# LPC8N04 register map
Vendor: nxp.com; File version: 1.0
CPU: CM0PLUS r0p0, little endian, no MPU, no FPU, VTOR, 2 interrupt priority bits
Registers are 32-bit, read-write, reset 0x0 unless marked. A register's access mark holds for its fields unless they carry their own. Offsets are from the block's base; [hi:lo] are bit positions; {n}, {i} and the like mark numbered series.

## TSENS — Temperature Sensor
Base 0x40060000
0x00 CR — Control register
  [0] START — sensor start bit. This bit is cleared by the temperature sensor at the end of the measurement.
0x04 DR — Data register. Contains result of conversion
  [15:0] DATA ro — Result of last conversion. Raw format is unsigned fixed point (0,5.11); calibrated format is signed (1, 9.6) 2-complement fixed point.
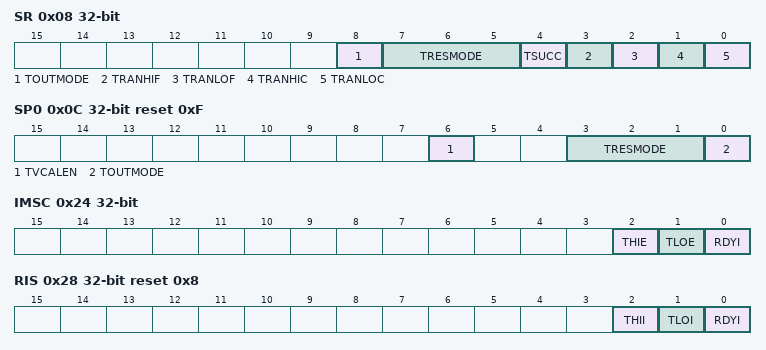
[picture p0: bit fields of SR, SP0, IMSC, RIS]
0x08 SR — Status register
  [8] TOUTMODE ro — used output mode
  [7:5] TRESMODE ro — used resolution mode
  [4] TSUCC ro — 1: successful conversion
  [3] TRANHIF ro — Fine range: 1: out of range (too large)
  [2] TRANLOF ro — Fine range: 1: out of range (too low)
  [1] TRANHIC ro — Coarse range: 1: out of range (too high)
  [0] TRANLOC ro — Coarse range: 1: out of range (too low)
0x0C SP0 reset 0xF — Setup register 0: set ADC and operation modes
  [6] TVCALEN — temperature sensor voltage calibration enable
  [3:1] TRESMODE — temperature sensor resolution mode. (0b010) 7 bit, (0b011) 8 bit, (0b100) 9 bit, (0b101) 10 bit, (0b110) 11 bits, (0b111) 12 bits (others not supported)
  [0] TOUTMODE — temperature sensor output mode. 0: raw data, 1: calibrated data
0x10 SP1 — Setup register 1: Calibration value 'A'
  [15:0] A — calibration factor ?A? unsigned fixed point (10.6)
0x14 SP2 — Setup register 2: Calibration value 'B'
  [15:0] B — calibration factor ?B? signed fixed point (10.6) 2-complement
0x18 SP3 — Setup register 3: Calibration value 'alpha'
  [15:0] ALPHA — calibration factor ?alpha? unsigned fixed point (6.10)
0x1C TLO — Low temperature threshold register
  [15:0] TLO — low-temperature threshold value in signed fixed point (10.6) 2-complement format.
0x20 THI — High temperature threshold register
  [15:0] THI — high-temperature threshold value in signed fixed point (10.6) 2-complement format.
0x24 IMSC — Interrupt Mask Set and Clear Register
  [2] THIE — Software should set this bit to enable interrupt when a temperature conversion is higher than the value stored in THI.
  [1] TLOE — Software should set this bit to enable interrupt when a temperature conversion is higher than the value stored in TLO.
  [0] RDYI — Software should set this bit to enable interrupt when a temperature conversion is ready on DR.
0x28 RIS reset 0x8 — Raw Interrupt Status Register
  [2] THII ro — This bit is 1 when a temperature conversion has finished and the value exceeds the threshold value set in the THI register
  [1] TLOI ro — This bit is 1 when a temperature conversion has finished and the value is below the threshold value set in the TLO register
  [0] RDYI ro — This bit is 1 when a temperature conversion has finished
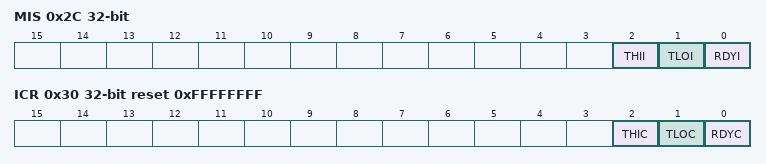
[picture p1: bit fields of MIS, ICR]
0x2C MIS — Masked Interrupt Status Register
  [2] THII ro — This bit is 1 when a temperature conversion has finished, if the value exceeds the threshold value set in the THI register, and this interrupt is enabled
  [1] TLOI ro — This bit is 1 when a temperature conversion has finished, if the value is below the threshold value set in the TLO register and this interrupt is enabled.
  [0] RDYI ro — This bit is 1 when a temperature conversion has finished and this interrupt is enabled.
0x30 ICR wo reset 0xFFFFFFFF — Interrupt Clear Register
  [2] THIC — Writing a 1 clears the temperature sensor high threshold interrupt
  [1] TLOC — Writing a 1 clears the temperature sensor low threshold interrupt
  [0] RDYC — Writing a 1 clears the temperature sensor conversion ready interrupt

## GPIO — General Purpose IO
Base 0x50000000
{0x0+4i} GPIODATA[{i}] (i=0..2047) — data address masking register locations for pins PIO0_0 to PIO0_11
  [11:0] DATA — logic levels for pins PIO0_0 to PIO0_11. HIGH = logic 1, LOW = logic 0
0x8000 DIR — Data direction register
  [11:0] IO — Selects pin x as input or output (x = 0 to 11). 0 = Pin PIOn_x is configured as input. 1 = Pin PIOn_x is configured as output.
0x8004 IS — Interrupt sense register
  [11:0] ISENSE — Selects interrupt on pin x as level or edge sensitive (x = 0 to11). 0 = Interrupt on pin PIOn_x is configured as edge sensitive. 1 = Interrupt on pin PIOn_x is configured as level sensitive.
0x8008 IBE — Interrupt both edges register
  [11:0] IBE — Selects interrupt on pin x to be triggered on both edges (x = 0 to 11). 0 = Interrupt on pin PIO_x is controlled through register GPIOIEV. 1 = Both edges on pin PIO_x trigger an interrupt.
0x800C IEV — Interrupt event register
  [11:0] IEV — Selects interrupt on pin x to be triggered rising or falling edges (x = 0 to 11). 0 = Depending on setting in register GPIOIS, falling edges or LOW level on pin PIO_x trigger an interrupt. 1 = Depending on setting in register GPIOIS, rising edges or HIGH level on pin PIO_x trigger an interrupt.
0x8010 IMSC — Interrupt mask register
  [11:0] MASK — Selects interrupt on pin x to be masked (x = 0 to 11). 0 = Interrupt on pin PIO_x is masked. 1 = Interrupt on pin PIO_x is not masked.
0x8014 RIS — Raw Interrupt status register
  [11:0] RAWST ro — Raw interrupt status (x = 0 to 11). 0 = No interrupt on pin PIO_x. 1 = Interrupt requirements met on PIO_x.
0x8018 MIS — Masked interrupt status register
  [11:0] MASK ro — Selects interrupt on pin x to be masked (x = 0 to 11). 0 = No interrupt or interrupt masked on pin PIO_x. 1 = Interrupt on PIO_x.
0x801C IC wo — Interrupt clear register
  [11:0] CLR — Selects interrupt on pin x to be cleared (x = 0 to 11). Clears the interrupt edge detection logic. This register is write-only. Remark: The synchronizer between the GPIO and the NVIC blocks causes a delay of 2 clocks. It is recommended to add two NOPs after the clear of the interrupt edge detection logic before the exit of the interrupt service routine. 0 = No effect. 1 = Clears edge detection logic for pin PIO_x.
